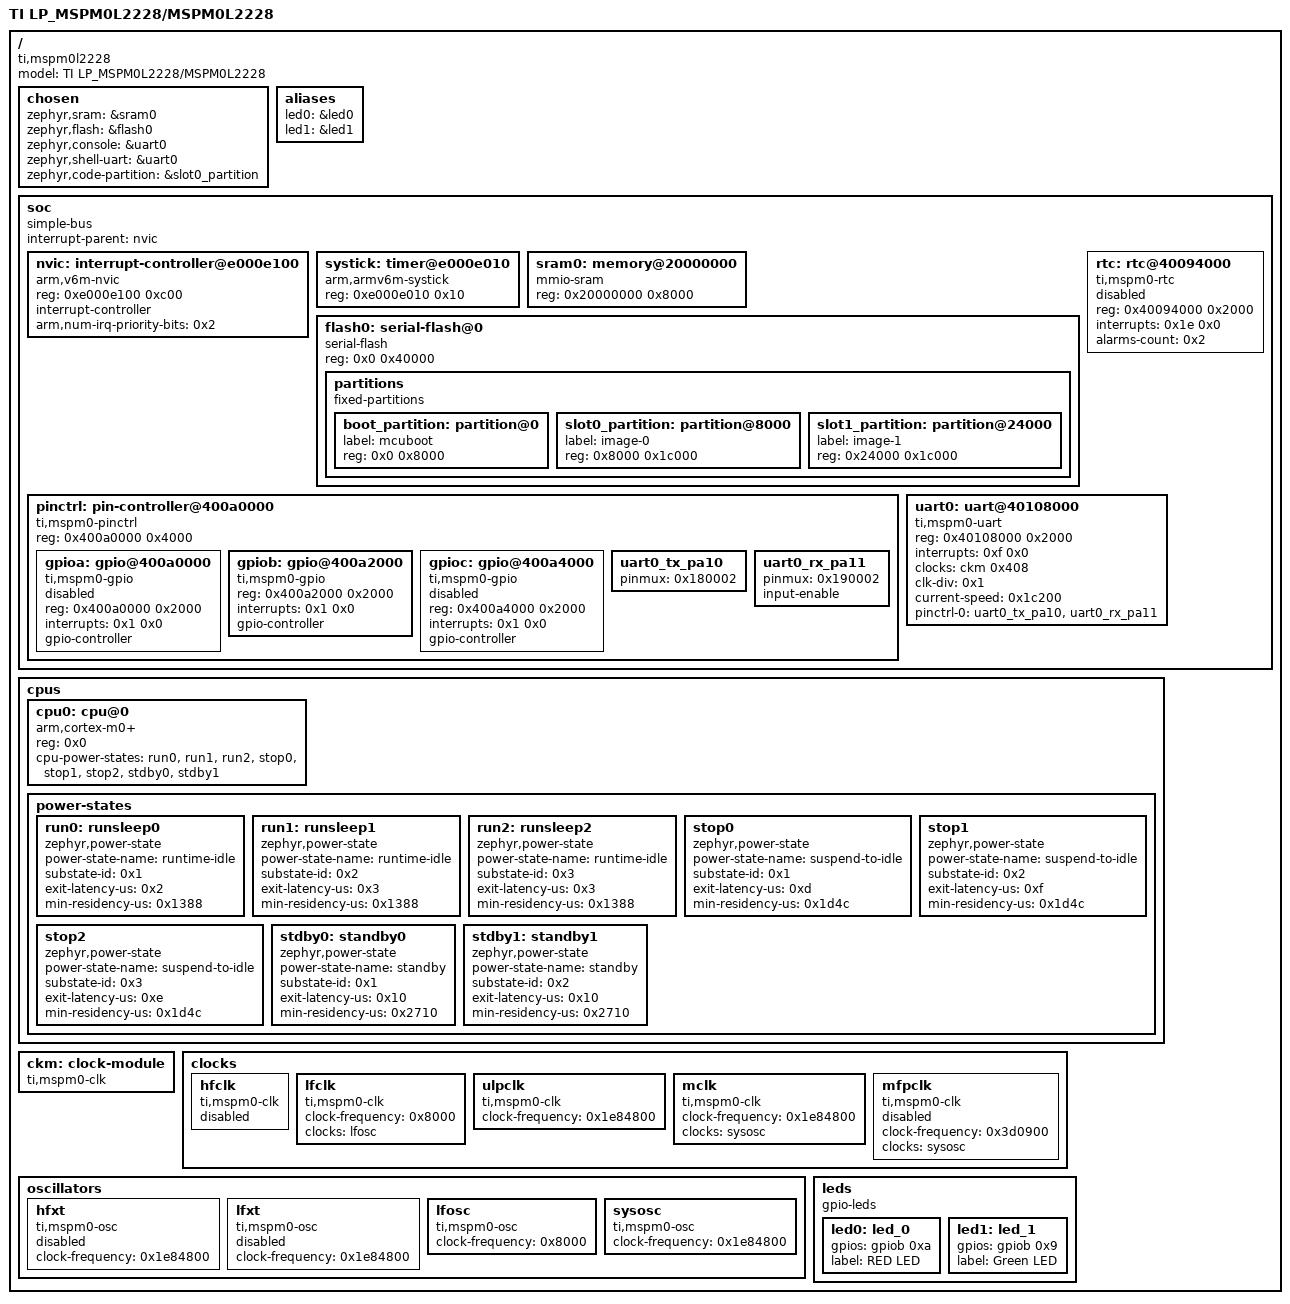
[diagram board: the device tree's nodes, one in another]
/dts-v1/;

/* node '/' defined in zephyr/dts/common/skeleton.dtsi:9 */
/ {
	#address-cells = < 0x1 >;              /* in zephyr/dts/common/skeleton.dtsi:10 */
	#size-cells = < 0x1 >;                 /* in zephyr/dts/common/skeleton.dtsi:11 */
	model = "TI LP_MSPM0L2228/MSPM0L2228"; /* in zephyr/boards/ti/lp_mspm0l2228/lp_mspm0l2228.dts:16 */
	compatible = "ti,mspm0l2228";          /* in zephyr/boards/ti/lp_mspm0l2228/lp_mspm0l2228.dts:17 */

	/* node '/chosen' defined in zephyr/dts/common/skeleton.dtsi:13 */
	chosen {
		zephyr,sram = &sram0;                     /* in zephyr/boards/ti/lp_mspm0l2228/lp_mspm0l2228.dts:25 */
		zephyr,flash = &flash0;                   /* in zephyr/boards/ti/lp_mspm0l2228/lp_mspm0l2228.dts:26 */
		zephyr,console = &uart0;                  /* in zephyr/boards/ti/lp_mspm0l2228/lp_mspm0l2228.dts:27 */
		zephyr,shell-uart = &uart0;               /* in zephyr/boards/ti/lp_mspm0l2228/lp_mspm0l2228.dts:28 */
		zephyr,code-partition = &slot0_partition; /* in zephyr/boards/ti/lp_mspm0l2228/lp_mspm0l2228.dts:29 */
	};

	/* node '/aliases' defined in zephyr/dts/common/skeleton.dtsi:15 */
	aliases {
		led0 = &led0; /* in zephyr/boards/ti/lp_mspm0l2228/lp_mspm0l2228.dts:20 */
		led1 = &led1; /* in zephyr/boards/ti/lp_mspm0l2228/lp_mspm0l2228.dts:21 */
	};

	/* node '/soc' defined in zephyr/dts/arm/armv6-m.dtsi:6 */
	soc {
		#address-cells = < 0x1 >;     /* in zephyr/dts/arm/armv6-m.dtsi:7 */
		#size-cells = < 0x1 >;        /* in zephyr/dts/arm/armv6-m.dtsi:8 */
		compatible = "simple-bus";    /* in zephyr/dts/arm/armv6-m.dtsi:9 */
		interrupt-parent = < &nvic >; /* in zephyr/dts/arm/armv6-m.dtsi:10 */
		ranges;                       /* in zephyr/dts/arm/armv6-m.dtsi:11 */

		/* node '/soc/interrupt-controller@e000e100' defined in zephyr/dts/arm/armv6-m.dtsi:13 */
		nvic: interrupt-controller@e000e100 {
			#address-cells = < 0x1 >;            /* in zephyr/dts/arm/armv6-m.dtsi:14 */
			compatible = "arm,v6m-nvic";         /* in zephyr/dts/arm/armv6-m.dtsi:15 */
			reg = < 0xe000e100 0xc00 >;          /* in zephyr/dts/arm/armv6-m.dtsi:16 */
			interrupt-controller;                /* in zephyr/dts/arm/armv6-m.dtsi:17 */
			#interrupt-cells = < 0x2 >;          /* in zephyr/dts/arm/armv6-m.dtsi:18 */
			arm,num-irq-priority-bits = < 0x2 >; /* in zephyr/dts/arm/ti/mspm0/mspm0.dtsi:203 */
			phandle = < 0x1 >;                   /* in zephyr/dts/arm/armv6-m.dtsi:10 */
		};

		/* node '/soc/timer@e000e010' defined in zephyr/dts/arm/armv6-m.dtsi:21 */
		systick: timer@e000e010 {
			compatible = "arm,armv6m-systick"; /* in zephyr/dts/arm/armv6-m.dtsi:22 */
			reg = < 0xe000e010 0x10 >;         /* in zephyr/dts/arm/armv6-m.dtsi:23 */
		};

		/* node '/soc/memory@20000000' defined in zephyr/dts/arm/ti/mspm0/mspm0.dtsi:149 */
		sram0: memory@20000000 {
			compatible = "mmio-sram";    /* in zephyr/dts/arm/ti/mspm0/mspm0.dtsi:150 */
			reg = < 0x20000000 0x8000 >; /* in zephyr/dts/arm/ti/mspm0/l/mspm0lx22x.dtsi:14 */
		};

		/* node '/soc/serial-flash@0' defined in zephyr/dts/arm/ti/mspm0/mspm0.dtsi:153 */
		flash0: serial-flash@0 {
			compatible = "serial-flash"; /* in zephyr/dts/arm/ti/mspm0/mspm0.dtsi:154 */
			reg = < 0x0 0x40000 >;       /* in zephyr/dts/arm/ti/mspm0/l/mspm0l2228.dtsi:14 */
			status = "okay";             /* in zephyr/boards/ti/lp_mspm0l2228/lp_mspm0l2228.dts:48 */

			/* node '/soc/serial-flash@0/partitions' defined in zephyr/boards/ti/lp_mspm0l2228/lp_mspm0l2228.dts:50 */
			partitions {
				compatible = "fixed-partitions"; /* in zephyr/boards/ti/lp_mspm0l2228/lp_mspm0l2228.dts:51 */
				#address-cells = < 0x1 >;        /* in zephyr/boards/ti/lp_mspm0l2228/lp_mspm0l2228.dts:52 */
				#size-cells = < 0x1 >;           /* in zephyr/boards/ti/lp_mspm0l2228/lp_mspm0l2228.dts:53 */

				/* node '/soc/serial-flash@0/partitions/partition@0' defined in zephyr/boards/ti/lp_mspm0l2228/lp_mspm0l2228.dts:55 */
				boot_partition: partition@0 {
					label = "mcuboot";    /* in zephyr/boards/ti/lp_mspm0l2228/lp_mspm0l2228.dts:56 */
					reg = < 0x0 0x8000 >; /* in zephyr/boards/ti/lp_mspm0l2228/lp_mspm0l2228.dts:57 */
				};

				/* node '/soc/serial-flash@0/partitions/partition@8000' defined in zephyr/boards/ti/lp_mspm0l2228/lp_mspm0l2228.dts:60 */
				slot0_partition: partition@8000 {
					label = "image-0";        /* in zephyr/boards/ti/lp_mspm0l2228/lp_mspm0l2228.dts:61 */
					reg = < 0x8000 0x1c000 >; /* in zephyr/boards/ti/lp_mspm0l2228/lp_mspm0l2228.dts:62 */
				};

				/* node '/soc/serial-flash@0/partitions/partition@24000' defined in zephyr/boards/ti/lp_mspm0l2228/lp_mspm0l2228.dts:65 */
				slot1_partition: partition@24000 {
					label = "image-1";         /* in zephyr/boards/ti/lp_mspm0l2228/lp_mspm0l2228.dts:66 */
					reg = < 0x24000 0x1c000 >; /* in zephyr/boards/ti/lp_mspm0l2228/lp_mspm0l2228.dts:67 */
				};
			};
		};

		/* node '/soc/rtc@40094000' defined in zephyr/dts/arm/ti/mspm0/mspm0.dtsi:157 */
		rtc: rtc@40094000 {
			compatible = "ti,mspm0-rtc"; /* in zephyr/dts/arm/ti/mspm0/mspm0.dtsi:158 */
			reg = < 0x40094000 0x2000 >; /* in zephyr/dts/arm/ti/mspm0/mspm0.dtsi:159 */
			interrupts = < 0x1e 0x0 >;   /* in zephyr/dts/arm/ti/mspm0/mspm0.dtsi:160 */
			alarms-count = < 0x2 >;      /* in zephyr/dts/arm/ti/mspm0/mspm0.dtsi:161 */
			status = "disabled";         /* in zephyr/dts/arm/ti/mspm0/mspm0.dtsi:162 */
		};

		/* node '/soc/pin-controller@400a0000' defined in zephyr/dts/arm/ti/mspm0/mspm0.dtsi:165 */
		pinctrl: pin-controller@400a0000 {
			compatible = "ti,mspm0-pinctrl"; /* in zephyr/dts/arm/ti/mspm0/mspm0.dtsi:166 */
			#address-cells = < 0x1 >;        /* in zephyr/dts/arm/ti/mspm0/mspm0.dtsi:167 */
			#size-cells = < 0x1 >;           /* in zephyr/dts/arm/ti/mspm0/mspm0.dtsi:168 */
			reg = < 0x400a0000 0x4000 >;     /* in zephyr/dts/arm/ti/mspm0/mspm0.dtsi:169 */
			status = "okay";                 /* in zephyr/boards/ti/lp_mspm0l2228/lp_mspm0l2228.dts:73 */

			/* node '/soc/pin-controller@400a0000/gpio@400a0000' defined in zephyr/dts/arm/ti/mspm0/mspm0.dtsi:171 */
			gpioa: gpio@400a0000 {
				compatible = "ti,mspm0-gpio"; /* in zephyr/dts/arm/ti/mspm0/mspm0.dtsi:172 */
				reg = < 0x400a0000 0x2000 >;  /* in zephyr/dts/arm/ti/mspm0/mspm0.dtsi:173 */
				interrupts = < 0x1 0x0 >;     /* in zephyr/dts/arm/ti/mspm0/mspm0.dtsi:174 */
				status = "disabled";          /* in zephyr/dts/arm/ti/mspm0/mspm0.dtsi:175 */
				gpio-controller;              /* in zephyr/dts/arm/ti/mspm0/mspm0.dtsi:176 */
				#gpio-cells = < 0x2 >;        /* in zephyr/dts/arm/ti/mspm0/mspm0.dtsi:177 */
			};

			/* node '/soc/pin-controller@400a0000/gpio@400a2000' defined in zephyr/dts/arm/ti/mspm0/mspm0.dtsi:180 */
			gpiob: gpio@400a2000 {
				compatible = "ti,mspm0-gpio"; /* in zephyr/dts/arm/ti/mspm0/mspm0.dtsi:181 */
				reg = < 0x400a2000 0x2000 >;  /* in zephyr/dts/arm/ti/mspm0/mspm0.dtsi:182 */
				interrupts = < 0x1 0x0 >;     /* in zephyr/dts/arm/ti/mspm0/mspm0.dtsi:183 */
				gpio-controller;              /* in zephyr/dts/arm/ti/mspm0/mspm0.dtsi:185 */
				#gpio-cells = < 0x2 >;        /* in zephyr/dts/arm/ti/mspm0/mspm0.dtsi:186 */
				status = "okay";              /* in zephyr/boards/ti/lp_mspm0l2228/lp_mspm0l2228.dts:77 */
				phandle = < 0xf >;            /* in zephyr/boards/ti/lp_mspm0l2228/lp_mspm0l2228.dts:36 */
			};

			/* node '/soc/pin-controller@400a0000/gpio@400a4000' defined in zephyr/dts/arm/ti/mspm0/l/mspm0l.dtsi:11 */
			gpioc: gpio@400a4000 {
				compatible = "ti,mspm0-gpio"; /* in zephyr/dts/arm/ti/mspm0/l/mspm0l.dtsi:12 */
				reg = < 0x400a4000 0x2000 >;  /* in zephyr/dts/arm/ti/mspm0/l/mspm0l.dtsi:13 */
				interrupts = < 0x1 0x0 >;     /* in zephyr/dts/arm/ti/mspm0/l/mspm0l.dtsi:14 */
				status = "disabled";          /* in zephyr/dts/arm/ti/mspm0/l/mspm0l.dtsi:15 */
				gpio-controller;              /* in zephyr/dts/arm/ti/mspm0/l/mspm0l.dtsi:16 */
				#gpio-cells = < 0x2 >;        /* in zephyr/dts/arm/ti/mspm0/l/mspm0l.dtsi:17 */
			};

			/* node '/soc/pin-controller@400a0000/uart0_tx_pa10' defined in modules/hal/ti/dts/ti/mspm0/l/mspm0l222x-pinctrl.dtsi:967 */
			uart0_tx_pa10: uart0_tx_pa10 {
				pinmux = < 0x180002 >; /* in modules/hal/ti/dts/ti/mspm0/l/mspm0l222x-pinctrl.dtsi:968 */
				phandle = < 0x3 >;     /* in zephyr/boards/ti/lp_mspm0l2228/lp_mspm0l2228.dts:83 */
			};

			/* node '/soc/pin-controller@400a0000/uart0_rx_pa11' defined in modules/hal/ti/dts/ti/mspm0/l/mspm0l222x-pinctrl.dtsi:1011 */
			uart0_rx_pa11: uart0_rx_pa11 {
				pinmux = < 0x190002 >; /* in modules/hal/ti/dts/ti/mspm0/l/mspm0l222x-pinctrl.dtsi:1012 */
				input-enable;          /* in modules/hal/ti/dts/ti/mspm0/l/mspm0l222x-pinctrl.dtsi:1013 */
				phandle = < 0x4 >;     /* in zephyr/boards/ti/lp_mspm0l2228/lp_mspm0l2228.dts:83 */
			};
		};

		/* node '/soc/uart@40108000' defined in zephyr/dts/arm/ti/mspm0/mspm0.dtsi:190 */
		uart0: uart@40108000 {
			compatible = "ti,mspm0-uart";                  /* in zephyr/dts/arm/ti/mspm0/mspm0.dtsi:191 */
			reg = < 0x40108000 0x2000 >;                   /* in zephyr/dts/arm/ti/mspm0/mspm0.dtsi:192 */
			interrupts = < 0xf 0x0 >;                      /* in zephyr/dts/arm/ti/mspm0/mspm0.dtsi:193 */
			clocks = < &ckm 0x408 >;                       /* in zephyr/dts/arm/ti/mspm0/mspm0.dtsi:195 */
			clk-div = < 0x1 >;                             /* in zephyr/dts/arm/ti/mspm0/mspm0.dtsi:196 */
			status = "okay";                               /* in zephyr/boards/ti/lp_mspm0l2228/lp_mspm0l2228.dts:81 */
			current-speed = < 0x1c200 >;                   /* in zephyr/boards/ti/lp_mspm0l2228/lp_mspm0l2228.dts:82 */
			pinctrl-0 = < &uart0_tx_pa10 &uart0_rx_pa11 >; /* in zephyr/boards/ti/lp_mspm0l2228/lp_mspm0l2228.dts:83 */
			pinctrl-names = "default";                     /* in zephyr/boards/ti/lp_mspm0l2228/lp_mspm0l2228.dts:84 */
		};
	};

	/* node '/cpus' defined in zephyr/dts/arm/ti/mspm0/mspm0.dtsi:13 */
	cpus {
		#address-cells = < 0x1 >; /* in zephyr/dts/arm/ti/mspm0/mspm0.dtsi:14 */
		#size-cells = < 0x0 >;    /* in zephyr/dts/arm/ti/mspm0/mspm0.dtsi:15 */

		/* node '/cpus/cpu@0' defined in zephyr/dts/arm/ti/mspm0/mspm0.dtsi:17 */
		cpu0: cpu@0 {
			device_type = "cpu";                                                           /* in zephyr/dts/arm/ti/mspm0/mspm0.dtsi:18 */
			compatible = "arm,cortex-m0+";                                                 /* in zephyr/dts/arm/ti/mspm0/mspm0.dtsi:19 */
			reg = < 0x0 >;                                                                 /* in zephyr/dts/arm/ti/mspm0/mspm0.dtsi:20 */
			#address-cells = < 0x1 >;                                                      /* in zephyr/dts/arm/ti/mspm0/mspm0.dtsi:21 */
			#size-cells = < 0x1 >;                                                         /* in zephyr/dts/arm/ti/mspm0/mspm0.dtsi:22 */
			cpu-power-states = < &run0 &run1 &run2 &stop0 &stop1 &stop2 &stdby0 &stdby1 >; /* in zephyr/dts/arm/ti/mspm0/mspm0.dtsi:23 */
		};

		/* node '/cpus/power-states' defined in zephyr/dts/arm/ti/mspm0/mspm0.dtsi:28 */
		power-states {

			/* node '/cpus/power-states/runsleep0' defined in zephyr/dts/arm/ti/mspm0/mspm0.dtsi:29 */
			run0: runsleep0 {
				compatible = "zephyr,power-state"; /* in zephyr/dts/arm/ti/mspm0/mspm0.dtsi:30 */
				power-state-name = "runtime-idle"; /* in zephyr/dts/arm/ti/mspm0/mspm0.dtsi:31 */
				substate-id = < 0x1 >;             /* in zephyr/dts/arm/ti/mspm0/mspm0.dtsi:32 */
				exit-latency-us = < 0x2 >;         /* in zephyr/dts/arm/ti/mspm0/l/mspm0l.dtsi:22 */
				min-residency-us = < 0x1388 >;     /* in zephyr/dts/arm/ti/mspm0/l/mspm0l.dtsi:23 */
				phandle = < 0x5 >;                 /* in zephyr/dts/arm/ti/mspm0/mspm0.dtsi:23 */
			};

			/* node '/cpus/power-states/runsleep1' defined in zephyr/dts/arm/ti/mspm0/mspm0.dtsi:35 */
			run1: runsleep1 {
				compatible = "zephyr,power-state"; /* in zephyr/dts/arm/ti/mspm0/mspm0.dtsi:36 */
				power-state-name = "runtime-idle"; /* in zephyr/dts/arm/ti/mspm0/mspm0.dtsi:37 */
				substate-id = < 0x2 >;             /* in zephyr/dts/arm/ti/mspm0/mspm0.dtsi:38 */
				exit-latency-us = < 0x3 >;         /* in zephyr/dts/arm/ti/mspm0/l/mspm0l.dtsi:27 */
				min-residency-us = < 0x1388 >;     /* in zephyr/dts/arm/ti/mspm0/l/mspm0l.dtsi:28 */
				phandle = < 0x6 >;                 /* in zephyr/dts/arm/ti/mspm0/mspm0.dtsi:23 */
			};

			/* node '/cpus/power-states/runsleep2' defined in zephyr/dts/arm/ti/mspm0/mspm0.dtsi:41 */
			run2: runsleep2 {
				compatible = "zephyr,power-state"; /* in zephyr/dts/arm/ti/mspm0/mspm0.dtsi:42 */
				power-state-name = "runtime-idle"; /* in zephyr/dts/arm/ti/mspm0/mspm0.dtsi:43 */
				substate-id = < 0x3 >;             /* in zephyr/dts/arm/ti/mspm0/mspm0.dtsi:44 */
				exit-latency-us = < 0x3 >;         /* in zephyr/dts/arm/ti/mspm0/l/mspm0l.dtsi:32 */
				min-residency-us = < 0x1388 >;     /* in zephyr/dts/arm/ti/mspm0/l/mspm0l.dtsi:33 */
				phandle = < 0x7 >;                 /* in zephyr/dts/arm/ti/mspm0/mspm0.dtsi:23 */
			};

			/* node '/cpus/power-states/stop0' defined in zephyr/dts/arm/ti/mspm0/mspm0.dtsi:47 */
			stop0: stop0 {
				compatible = "zephyr,power-state";    /* in zephyr/dts/arm/ti/mspm0/mspm0.dtsi:48 */
				power-state-name = "suspend-to-idle"; /* in zephyr/dts/arm/ti/mspm0/mspm0.dtsi:49 */
				substate-id = < 0x1 >;                /* in zephyr/dts/arm/ti/mspm0/mspm0.dtsi:50 */
				exit-latency-us = < 0xd >;            /* in zephyr/dts/arm/ti/mspm0/l/mspm0l.dtsi:37 */
				min-residency-us = < 0x1d4c >;        /* in zephyr/dts/arm/ti/mspm0/l/mspm0l.dtsi:38 */
				phandle = < 0x8 >;                    /* in zephyr/dts/arm/ti/mspm0/mspm0.dtsi:23 */
			};

			/* node '/cpus/power-states/stop1' defined in zephyr/dts/arm/ti/mspm0/mspm0.dtsi:53 */
			stop1: stop1 {
				compatible = "zephyr,power-state";    /* in zephyr/dts/arm/ti/mspm0/mspm0.dtsi:54 */
				power-state-name = "suspend-to-idle"; /* in zephyr/dts/arm/ti/mspm0/mspm0.dtsi:55 */
				substate-id = < 0x2 >;                /* in zephyr/dts/arm/ti/mspm0/mspm0.dtsi:56 */
				exit-latency-us = < 0xf >;            /* in zephyr/dts/arm/ti/mspm0/l/mspm0l.dtsi:42 */
				min-residency-us = < 0x1d4c >;        /* in zephyr/dts/arm/ti/mspm0/l/mspm0l.dtsi:43 */
				phandle = < 0x9 >;                    /* in zephyr/dts/arm/ti/mspm0/mspm0.dtsi:23 */
			};

			/* node '/cpus/power-states/stop2' defined in zephyr/dts/arm/ti/mspm0/mspm0.dtsi:59 */
			stop2: stop2 {
				compatible = "zephyr,power-state";    /* in zephyr/dts/arm/ti/mspm0/mspm0.dtsi:60 */
				power-state-name = "suspend-to-idle"; /* in zephyr/dts/arm/ti/mspm0/mspm0.dtsi:61 */
				substate-id = < 0x3 >;                /* in zephyr/dts/arm/ti/mspm0/mspm0.dtsi:62 */
				exit-latency-us = < 0xe >;            /* in zephyr/dts/arm/ti/mspm0/l/mspm0l.dtsi:47 */
				min-residency-us = < 0x1d4c >;        /* in zephyr/dts/arm/ti/mspm0/l/mspm0l.dtsi:48 */
				phandle = < 0xa >;                    /* in zephyr/dts/arm/ti/mspm0/mspm0.dtsi:23 */
			};

			/* node '/cpus/power-states/standby0' defined in zephyr/dts/arm/ti/mspm0/mspm0.dtsi:65 */
			stdby0: standby0 {
				compatible = "zephyr,power-state"; /* in zephyr/dts/arm/ti/mspm0/mspm0.dtsi:66 */
				power-state-name = "standby";      /* in zephyr/dts/arm/ti/mspm0/mspm0.dtsi:67 */
				substate-id = < 0x1 >;             /* in zephyr/dts/arm/ti/mspm0/mspm0.dtsi:68 */
				exit-latency-us = < 0x10 >;        /* in zephyr/dts/arm/ti/mspm0/l/mspm0l.dtsi:52 */
				min-residency-us = < 0x2710 >;     /* in zephyr/dts/arm/ti/mspm0/l/mspm0l.dtsi:53 */
				phandle = < 0xb >;                 /* in zephyr/dts/arm/ti/mspm0/mspm0.dtsi:23 */
			};

			/* node '/cpus/power-states/standby1' defined in zephyr/dts/arm/ti/mspm0/mspm0.dtsi:71 */
			stdby1: standby1 {
				compatible = "zephyr,power-state"; /* in zephyr/dts/arm/ti/mspm0/mspm0.dtsi:72 */
				power-state-name = "standby";      /* in zephyr/dts/arm/ti/mspm0/mspm0.dtsi:73 */
				substate-id = < 0x2 >;             /* in zephyr/dts/arm/ti/mspm0/mspm0.dtsi:74 */
				exit-latency-us = < 0x10 >;        /* in zephyr/dts/arm/ti/mspm0/l/mspm0l.dtsi:57 */
				min-residency-us = < 0x2710 >;     /* in zephyr/dts/arm/ti/mspm0/l/mspm0l.dtsi:58 */
				phandle = < 0xc >;                 /* in zephyr/dts/arm/ti/mspm0/mspm0.dtsi:23 */
			};
		};
	};

	/* node '/clock-module' defined in zephyr/dts/arm/ti/mspm0/mspm0.dtsi:79 */
	ckm: clock-module {
		compatible = "ti,mspm0-clk"; /* in zephyr/dts/arm/ti/mspm0/mspm0.dtsi:80 */
		#clock-cells = < 0x1 >;      /* in zephyr/dts/arm/ti/mspm0/mspm0.dtsi:81 */
		phandle = < 0x2 >;           /* in zephyr/dts/arm/ti/mspm0/mspm0.dtsi:195 */
	};

	/* node '/clocks' defined in zephyr/dts/arm/ti/mspm0/mspm0.dtsi:84 */
	clocks: clocks {

		/* node '/clocks/hfclk' defined in zephyr/dts/arm/ti/mspm0/mspm0.dtsi:85 */
		hfclk: hfclk {
			#clock-cells = < 0x1 >;      /* in zephyr/dts/arm/ti/mspm0/mspm0.dtsi:86 */
			compatible = "ti,mspm0-clk"; /* in zephyr/dts/arm/ti/mspm0/mspm0.dtsi:87 */
			status = "disabled";         /* in zephyr/dts/arm/ti/mspm0/mspm0.dtsi:88 */
		};

		/* node '/clocks/lfclk' defined in zephyr/dts/arm/ti/mspm0/mspm0.dtsi:91 */
		lfclk: lfclk {
			#clock-cells = < 0x1 >;       /* in zephyr/dts/arm/ti/mspm0/mspm0.dtsi:92 */
			compatible = "ti,mspm0-clk";  /* in zephyr/dts/arm/ti/mspm0/mspm0.dtsi:93 */
			clock-frequency = < 0x8000 >; /* in zephyr/dts/arm/ti/mspm0/mspm0.dtsi:94 */
			clocks = < &lfosc >;          /* in zephyr/dts/arm/ti/mspm0/mspm0.dtsi:95 */
		};

		/* node '/clocks/ulpclk' defined in zephyr/dts/arm/ti/mspm0/mspm0.dtsi:98 */
		ulpclk: ulpclk {
			#clock-cells = < 0x1 >;          /* in zephyr/dts/arm/ti/mspm0/mspm0.dtsi:99 */
			compatible = "ti,mspm0-clk";     /* in zephyr/dts/arm/ti/mspm0/mspm0.dtsi:100 */
			clock-frequency = < 0x1e84800 >; /* in zephyr/dts/arm/ti/mspm0/mspm0.dtsi:101 */
		};

		/* node '/clocks/mclk' defined in zephyr/dts/arm/ti/mspm0/mspm0.dtsi:104 */
		mclk: mclk {
			#clock-cells = < 0x1 >;          /* in zephyr/dts/arm/ti/mspm0/mspm0.dtsi:105 */
			compatible = "ti,mspm0-clk";     /* in zephyr/dts/arm/ti/mspm0/mspm0.dtsi:106 */
			clock-frequency = < 0x1e84800 >; /* in zephyr/dts/arm/ti/mspm0/mspm0.dtsi:107 */
			clocks = < &sysosc >;            /* in zephyr/dts/arm/ti/mspm0/mspm0.dtsi:108 */
		};

		/* node '/clocks/mfpclk' defined in zephyr/dts/arm/ti/mspm0/mspm0.dtsi:111 */
		mfpclk: mfpclk {
			#clock-cells = < 0x1 >;         /* in zephyr/dts/arm/ti/mspm0/mspm0.dtsi:112 */
			compatible = "ti,mspm0-clk";    /* in zephyr/dts/arm/ti/mspm0/mspm0.dtsi:113 */
			clock-frequency = < 0x3d0900 >; /* in zephyr/dts/arm/ti/mspm0/mspm0.dtsi:114 */
			clocks = < &sysosc >;           /* in zephyr/dts/arm/ti/mspm0/mspm0.dtsi:115 */
			status = "disabled";            /* in zephyr/dts/arm/ti/mspm0/mspm0.dtsi:116 */
		};
	};

	/* node '/oscillators' defined in zephyr/dts/arm/ti/mspm0/mspm0.dtsi:120 */
	oscillators: oscillators {

		/* node '/oscillators/hfxt' defined in zephyr/dts/arm/ti/mspm0/mspm0.dtsi:121 */
		hfxt: hfxt {
			#clock-cells = < 0x0 >;          /* in zephyr/dts/arm/ti/mspm0/mspm0.dtsi:122 */
			compatible = "ti,mspm0-osc";     /* in zephyr/dts/arm/ti/mspm0/mspm0.dtsi:123 */
			clock-frequency = < 0x1e84800 >; /* in zephyr/dts/arm/ti/mspm0/mspm0.dtsi:124 */
			status = "disabled";             /* in zephyr/dts/arm/ti/mspm0/mspm0.dtsi:125 */
		};

		/* node '/oscillators/lfxt' defined in zephyr/dts/arm/ti/mspm0/mspm0.dtsi:128 */
		lfxt: lfxt {
			#clock-cells = < 0x0 >;          /* in zephyr/dts/arm/ti/mspm0/mspm0.dtsi:129 */
			compatible = "ti,mspm0-osc";     /* in zephyr/dts/arm/ti/mspm0/mspm0.dtsi:130 */
			clock-frequency = < 0x1e84800 >; /* in zephyr/dts/arm/ti/mspm0/mspm0.dtsi:131 */
			status = "disabled";             /* in zephyr/dts/arm/ti/mspm0/mspm0.dtsi:132 */
		};

		/* node '/oscillators/lfosc' defined in zephyr/dts/arm/ti/mspm0/mspm0.dtsi:135 */
		lfosc: lfosc {
			#clock-cells = < 0x0 >;       /* in zephyr/dts/arm/ti/mspm0/mspm0.dtsi:136 */
			compatible = "ti,mspm0-osc";  /* in zephyr/dts/arm/ti/mspm0/mspm0.dtsi:137 */
			clock-frequency = < 0x8000 >; /* in zephyr/dts/arm/ti/mspm0/mspm0.dtsi:138 */
			phandle = < 0xd >;            /* in zephyr/dts/arm/ti/mspm0/mspm0.dtsi:95 */
		};

		/* node '/oscillators/sysosc' defined in zephyr/dts/arm/ti/mspm0/mspm0.dtsi:141 */
		sysosc: sysosc {
			#clock-cells = < 0x0 >;          /* in zephyr/dts/arm/ti/mspm0/mspm0.dtsi:142 */
			compatible = "ti,mspm0-osc";     /* in zephyr/dts/arm/ti/mspm0/mspm0.dtsi:143 */
			clock-frequency = < 0x1e84800 >; /* in zephyr/dts/arm/ti/mspm0/mspm0.dtsi:144 */
			phandle = < 0xe >;               /* in zephyr/dts/arm/ti/mspm0/mspm0.dtsi:108 */
		};
	};

	/* node '/leds' defined in zephyr/boards/ti/lp_mspm0l2228/lp_mspm0l2228.dts:32 */
	leds {
		compatible = "gpio-leds"; /* in zephyr/boards/ti/lp_mspm0l2228/lp_mspm0l2228.dts:33 */

		/* node '/leds/led_0' defined in zephyr/boards/ti/lp_mspm0l2228/lp_mspm0l2228.dts:35 */
		led0: led_0 {
			gpios = < &gpiob 0xa 0x0 >; /* in zephyr/boards/ti/lp_mspm0l2228/lp_mspm0l2228.dts:36 */
			label = "RED LED";          /* in zephyr/boards/ti/lp_mspm0l2228/lp_mspm0l2228.dts:37 */
		};

		/* node '/leds/led_1' defined in zephyr/boards/ti/lp_mspm0l2228/lp_mspm0l2228.dts:40 */
		led1: led_1 {
			gpios = < &gpiob 0x9 0x0 >; /* in zephyr/boards/ti/lp_mspm0l2228/lp_mspm0l2228.dts:41 */
			label = "Green LED";        /* in zephyr/boards/ti/lp_mspm0l2228/lp_mspm0l2228.dts:42 */
		};
	};
};
